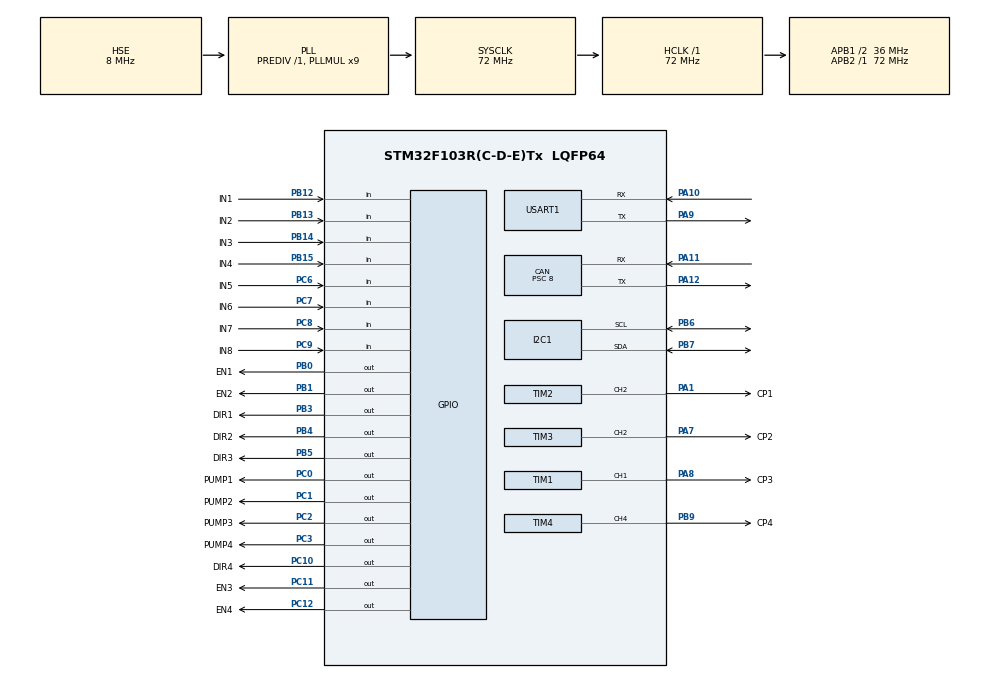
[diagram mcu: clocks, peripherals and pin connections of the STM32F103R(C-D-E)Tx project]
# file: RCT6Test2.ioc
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CAN.BS1=CAN_BS1_5TQ
CAN.BS2=CAN_BS2_3TQ
CAN.CalculateBaudRate=500000
CAN.CalculateTimeBit=2000
CAN.CalculateTimeQuantum=222.22222222222223
CAN.Prescaler=8
CAN.SJW=CAN_SJW_2TQ
Mcu.Family=STM32F1
Mcu.Name=STM32F103R(C-D-E)Tx
Mcu.Package=LQFP64
NVIC.PriorityGroup=NVIC_PRIORITYGROUP_4
NVIC.TIM1_CC_IRQn=true\:0\:0\:false\:false\:true\:true\:true\:true
NVIC.TIM2_IRQn=true\:2\:0\:true\:false\:true\:true\:true\:true
NVIC.TIM3_IRQn=true\:2\:0\:true\:false\:true\:true\:true\:true
NVIC.TIM4_IRQn=true\:2\:0\:true\:false\:true\:true\:true\:true
NVIC.USART1_IRQn=true\:0\:0\:false\:false\:true\:true\:true\:true
NVIC.USB_LP_CAN1_RX0_IRQn=true\:0\:0\:false\:false\:true\:true\:true\:true
PA1.GPIO_Label=CP1
PA1.Signal=S_TIM2_CH2
PA10.Mode=Asynchronous
PA10.Signal=USART1_RX
PA11.Mode=CAN_Activate
PA11.Signal=CAN_RX
PA12.Mode=CAN_Activate
PA12.Signal=CAN_TX
PA13.Mode=Serial_Wire
PA13.Signal=SYS_JTMS-SWDIO
PA14.Mode=Serial_Wire
PA14.Signal=SYS_JTCK-SWCLK
PA7.GPIO_Label=CP2
PA7.Signal=S_TIM3_CH2
PA8.GPIO_Label=CP3
PA8.Signal=S_TIM1_CH1
PA9.Mode=Asynchronous
PA9.Signal=USART1_TX
PB0.GPIO_Label=EN1
PB0.Signal=GPIO_Output
PB1.GPIO_Label=EN2
PB1.Signal=GPIO_Output
PB12.GPIO_Label=IN1
PB12.Signal=GPIO_Input
PB13.GPIO_Label=IN2
PB13.Signal=GPIO_Input
PB14.GPIO_Label=IN3
PB14.Signal=GPIO_Input
PB15.GPIO_Label=IN4
PB15.Signal=GPIO_Input
PB3.GPIO_Label=DIR1
PB3.Signal=GPIO_Output
PB4.GPIO_Label=DIR2
PB4.Signal=GPIO_Output
PB5.GPIO_Label=DIR3
PB5.Signal=GPIO_Output
PB6.Mode=I2C
PB6.Signal=I2C1_SCL
PB7.Mode=I2C
PB7.Signal=I2C1_SDA
PB9.GPIO_Label=CP4
PB9.Signal=S_TIM4_CH4
PC0.GPIO_Label=PUMP1
PC0.Signal=GPIO_Output
PC1.GPIO_Label=PUMP2
PC1.Signal=GPIO_Output
PC10.GPIO_Label=DIR4
PC10.Signal=GPIO_Output
PC11.GPIO_Label=EN3
PC11.Signal=GPIO_Output
PC12.GPIO_Label=EN4
PC12.Signal=GPIO_Output
PC2.GPIO_Label=PUMP3
PC2.Signal=GPIO_Output
PC3.GPIO_Label=PUMP4
PC3.Signal=GPIO_Output
PC6.GPIO_Label=IN5
PC6.Signal=GPIO_Input
PC7.GPIO_Label=IN6
PC7.Signal=GPIO_Input
PC8.GPIO_Label=IN7
PC8.Signal=GPIO_Input
PC9.GPIO_Label=IN8
PC9.Signal=GPIO_Input
PD0-OSC_IN.Mode=HSE-External-Oscillator
PD0-OSC_IN.Signal=RCC_OSC_IN
PD1-OSC_OUT.Mode=HSE-External-Oscillator
PD1-OSC_OUT.Signal=RCC_OSC_OUT
ProjectManager.HeapSize=0x200
ProjectManager.StackSize=0x400
ProjectManager.TargetToolchain=MDK-ARM V5.32
RCC.AHBFreq_Value=72000000
RCC.APB1CLKDivider=RCC_HCLK_DIV2
RCC.APB1Freq_Value=36000000
RCC.APB1TimFreq_Value=72000000
RCC.APB2Freq_Value=72000000
RCC.APB2TimFreq_Value=72000000
RCC.HCLKFreq_Value=72000000
RCC.PLLMUL=RCC_PLL_MUL9
RCC.PLLSourceVirtual=RCC_PLLSOURCE_HSE
RCC.SYSCLKFreq_VALUE=72000000
RCC.SYSCLKSource=RCC_SYSCLKSOURCE_PLLCLK
RCC.USBFreq_Value=72000000
SH.S_TIM1_CH1.0=TIM1_CH1,Output Compare1 CH1
SH.S_TIM2_CH2.0=TIM2_CH2,PWM Generation2 CH2
SH.S_TIM3_CH2.0=TIM3_CH2,PWM Generation2 CH2
SH.S_TIM4_CH4.0=TIM4_CH4,PWM Generation4 CH4
TIM1.AutoReloadPreload=TIM_AUTORELOAD_PRELOAD_ENABLE
TIM1.Channel-Output\ Compare1\ CH1=TIM_CHANNEL_1
TIM1.OCMode_1=TIM_OCMODE_TOGGLE
TIM1.Period=0xFFFF-1
TIM1.Prescaler=1
TIM2.AutoReloadPreload=TIM_AUTORELOAD_PRELOAD_ENABLE
TIM2.Channel-PWM\ Generation2\ CH2=TIM_CHANNEL_2
TIM2.OCMode_PWM-PWM\ Generation2\ CH2=TIM_OCMODE_PWM1
TIM2.Period=1000
TIM2.Prescaler=72-1
TIM2.Pulse-PWM\ Generation2\ CH2=0
TIM3.AutoReloadPreload=TIM_AUTORELOAD_PRELOAD_ENABLE
TIM3.Channel-PWM\ Generation2\ CH2=TIM_CHANNEL_2
TIM3.Period=1000
TIM3.Prescaler=72-1
TIM4.AutoReloadPreload=TIM_AUTORELOAD_PRELOAD_ENABLE
TIM4.Channel-PWM\ Generation4\ CH4=TIM_CHANNEL_4
TIM4.OCMode_PWM-PWM\ Generation4\ CH4=TIM_OCMODE_PWM1
TIM4.Period=1000
TIM4.Prescaler=72-1
TIM4.Pulse-PWM\ Generation4\ CH4=0
USART1.VirtualMode=VM_ASYNC
VP_TIM1_VS_ClockSourceINT.Mode=Internal
VP_TIM2_VS_ClockSourceINT.Mode=Internal
VP_TIM3_VS_ClockSourceINT.Mode=Internal
VP_TIM4_VS_ClockSourceINT.Mode=Internal
board=custom

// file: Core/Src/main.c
/* USER CODE BEGIN Header */
/**
  ******************************************************************************
  * @file           : main.c
  * @brief          : Main program body
  ******************************************************************************
  * @attention
  *
  * Copyright (c) 2025 STMicroelectronics.
  * All rights reserved.
  *
  * This software is licensed under terms that can be found in the LICENSE file
  * in the root directory of this software component.
  * If no LICENSE file comes with this software, it is provided AS-IS.
  *
  ******************************************************************************
  */
/* USER CODE END Header */
#include "main.h"
#include "can.h"
#include "i2c.h"
#include "tim.h"
#include "usart.h"
#include "gpio.h"

/* USER CODE BEGIN Includes */
#include "work_interface.h"
/* USER CODE END Includes */

void SystemClock_Config(void);

int main(void)
{

  /* MCU Configuration--------------------------------------------------------*/

  /* Reset of all peripherals, Initializes the Flash interface and the Systick. */
  HAL_Init();

  /* Configure the system clock */
  SystemClock_Config();

  /* Initialize all configured peripherals */
  MX_GPIO_Init();
  MX_I2C1_Init();
  MX_USART1_UART_Init();
  MX_TIM1_Init();
  MX_TIM2_Init();
  MX_TIM3_Init();
  MX_TIM4_Init();
  MX_CAN_Init();
  /* USER CODE BEGIN 2 */
	sysInit();
  /* USER CODE END 2 */

  /* Infinite loop */
  while (1)
  {

    /* USER CODE BEGIN 3 */
				test();
  }
  /* USER CODE END 3 */
}

void SystemClock_Config(void)
{
  RCC_OscInitTypeDef RCC_OscInitStruct = {0};
  RCC_ClkInitTypeDef RCC_ClkInitStruct = {0};

  /** Initializes the RCC Oscillators according to the specified parameters
  * in the RCC_OscInitTypeDef structure.
  */
  RCC_OscInitStruct.OscillatorType = RCC_OSCILLATORTYPE_HSE;
  RCC_OscInitStruct.HSEState = RCC_HSE_ON;
  RCC_OscInitStruct.HSEPredivValue = RCC_HSE_PREDIV_DIV1;
  RCC_OscInitStruct.HSIState = RCC_HSI_ON;
  RCC_OscInitStruct.PLL.PLLState = RCC_PLL_ON;
  RCC_OscInitStruct.PLL.PLLSource = RCC_PLLSOURCE_HSE;
  RCC_OscInitStruct.PLL.PLLMUL = RCC_PLL_MUL9;
  if (HAL_RCC_OscConfig(&RCC_OscInitStruct) != HAL_OK)
  {
    Error_Handler();
  }

  /** Initializes the CPU, AHB and APB buses clocks
  */
  RCC_ClkInitStruct.ClockType = RCC_CLOCKTYPE_HCLK|RCC_CLOCKTYPE_SYSCLK
                              |RCC_CLOCKTYPE_PCLK1|RCC_CLOCKTYPE_PCLK2;
  RCC_ClkInitStruct.SYSCLKSource = RCC_SYSCLKSOURCE_PLLCLK;
  RCC_ClkInitStruct.AHBCLKDivider = RCC_SYSCLK_DIV1;
  RCC_ClkInitStruct.APB1CLKDivider = RCC_HCLK_DIV2;
  RCC_ClkInitStruct.APB2CLKDivider = RCC_HCLK_DIV1;

  if (HAL_RCC_ClockConfig(&RCC_ClkInitStruct, FLASH_LATENCY_2) != HAL_OK)
  {
    Error_Handler();
  }
}

void Error_Handler(void)
{
  __disable_irq();
  while (1)
  {
  }
}
